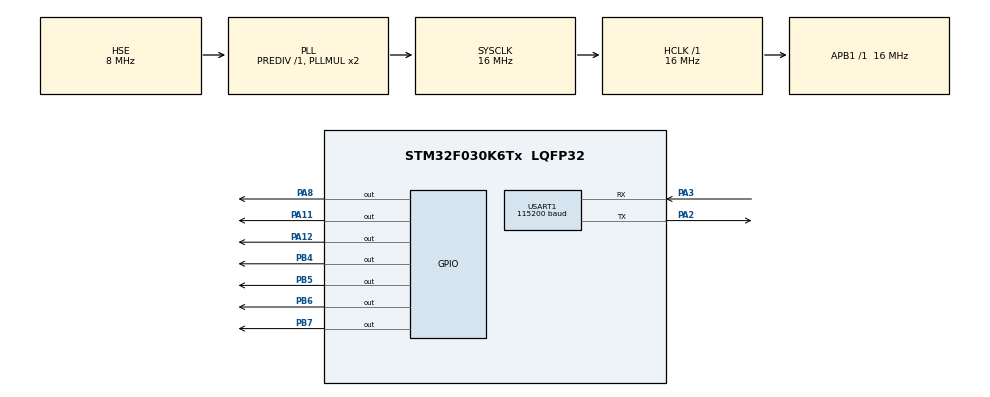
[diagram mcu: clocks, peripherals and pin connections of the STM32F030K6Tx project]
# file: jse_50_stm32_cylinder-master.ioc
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Mcu.Family=STM32F0
Mcu.Name=STM32F030K6Tx
Mcu.Package=LQFP32
NVIC.TIM3_IRQn=true\:2\:0\:true\:false\:true\:true\:true
NVIC.USART1_IRQn=true\:1\:0\:true\:false\:true\:true\:true
PA11.Signal=GPIO_Output
PA12.GPIO_ModeDefaultOutputPP=GPIO_MODE_OUTPUT_PP
PA12.GPIO_PuPd=GPIO_NOPULL
PA12.GPIO_Speed=GPIO_SPEED_FREQ_LOW
PA12.PinState=GPIO_PIN_RESET
PA12.Signal=GPIO_Output
PA2.Mode=Asynchronous
PA2.Signal=USART1_TX
PA3.Mode=Asynchronous
PA3.Signal=USART1_RX
PA8.GPIO_ModeDefaultOutputPP=GPIO_MODE_OUTPUT_PP
PA8.GPIO_PuPd=GPIO_NOPULL
PA8.GPIO_Speed=GPIO_SPEED_FREQ_LOW
PA8.PinState=GPIO_PIN_RESET
PA8.Signal=GPIO_Output
PB4.GPIO_ModeDefaultOutputPP=GPIO_MODE_OUTPUT_PP
PB4.GPIO_PuPd=GPIO_NOPULL
PB4.GPIO_Speed=GPIO_SPEED_FREQ_LOW
PB4.PinState=GPIO_PIN_RESET
PB4.Signal=GPIO_Output
PB5.GPIO_ModeDefaultOutputPP=GPIO_MODE_OUTPUT_PP
PB5.GPIO_PuPd=GPIO_NOPULL
PB5.GPIO_Speed=GPIO_SPEED_FREQ_LOW
PB5.PinState=GPIO_PIN_RESET
PB5.Signal=GPIO_Output
PB6.GPIO_FM6=__NULL
PB6.GPIO_ModeDefaultOutputPP=GPIO_MODE_OUTPUT_PP
PB6.GPIO_PuPd=GPIO_NOPULL
PB6.GPIO_Speed=GPIO_SPEED_FREQ_LOW
PB6.PinState=GPIO_PIN_RESET
PB6.Signal=GPIO_Output
PB7.GPIO_FM7=__NULL
PB7.GPIO_ModeDefaultOutputPP=GPIO_MODE_OUTPUT_PP
PB7.GPIO_PuPd=GPIO_NOPULL
PB7.GPIO_Speed=GPIO_SPEED_FREQ_LOW
PB7.PinState=GPIO_PIN_RESET
PB7.Signal=GPIO_Output
PF0-OSC_IN.Mode=HSE-External-Oscillator
PF0-OSC_IN.Signal=RCC_OSC_IN
PF1-OSC_OUT.Mode=HSE-External-Oscillator
PF1-OSC_OUT.Signal=RCC_OSC_OUT
ProjectManager.HeapSize=0x200
ProjectManager.StackSize=0x400
ProjectManager.TargetToolchain=STM32CubeIDE
RCC.AHBFreq_Value=16000000
RCC.APB1Freq_Value=16000000
RCC.APB1TimFreq_Value=16000000
RCC.HCLKFreq_Value=16000000
RCC.PLLSourceVirtual=RCC_PLLSOURCE_HSE
RCC.PWREXT_OverDrive=PWREXT_OverDrive_ACTIVATED
RCC.PWR_Regulator_Voltage_Scale=PWR_REGULATOR_VOLTAGE_SCALE1
RCC.RCC_TIM_PRescaler_Selection=RCC_TIMPRES_DESACTIVATED
RCC.SYSCLKFreq_VALUE=16000000
RCC.SYSCLKSource=RCC_SYSCLKSOURCE_PLLCLK
TIM3.Channel-Output\ Compare1\ No\ Output=TIM_CHANNEL_1
TIM3.Period=500
TIM3.Prescaler=15999
USART1.BaudRate=115200
USART1.VirtualMode-Asynchronous=VM_ASYNC
VP_TIM3_VS_ClockSourceINT.Mode=Internal
VP_TIM3_VS_no_output1.Mode=Output Compare1 No Output
board=custom

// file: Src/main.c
/* USER CODE BEGIN Header */
/**
 ******************************************************************************
 * @file           : main.c
 * @brief          : Main program body
 ******************************************************************************
 * @attention
 *
 * <h2><center>&copy; Copyright (c) 2019 STMicroelectronics.
 * All rights reserved.</center></h2>
 *
 * This software component is licensed by ST under BSD 3-Clause license,
 * the "License"; You may not use this file except in compliance with the
 * License. You may obtain a copy of the License at:
 *                        opensource.org/licenses/BSD-3-Clause
 *
 ******************************************************************************
 */
/* USER CODE END Header */

#include "main.h"
#include "tim.h"
#include "usart.h"
#include "gpio.h"

/* USER CODE BEGIN Includes */

#include "led.h"
#include "ctrl.h"
#include "address.h"

/* USER CODE END Includes */

void SystemClock_Config(void);

int main(void)
{

  /* MCU Configuration--------------------------------------------------------*/

  /* Reset of all peripherals, Initializes the Flash interface and the Systick. */
  HAL_Init();

  /* Configure the system clock */
  SystemClock_Config();

  /* Initialize all configured peripherals */
  MX_GPIO_Init();
  MX_TIM3_Init();
  MX_USART1_UART_Init();
  /* USER CODE BEGIN 2 */

	CTRL_Init();
//	HAL_TIM_Base_Start_IT(&htim3);
	HAL_TIM_OC_Start_IT(&htim3,TIM_CHANNEL_1);

  /* USER CODE END 2 */

  /* Infinite loop */
  /* USER CODE BEGIN WHILE */
//	while (ADDRESS_INDEX == 0xFF)
		;
//		htim3.Instance->CCR1 = 500;
	while (1) {
//		CTRL_Work();
		HAL_Delay(5000);
//		TIM1->CCR1=160;
	//	htim3.Instance->CCR1 = 500;
//		htim1.Init.Period = 80;
//		HAL_TIM_Base_DeInit(&htim1);
//		HAL_TIM_Base_Start_IT(&htim1);

//		htim1.Instance->CNT = 0;
//		HAL_TIM_Base_Stop_IT(&htim1);
//		HAL_TIM_Base_Start_IT(&htim1);

    /* USER CODE END WHILE */

	}
}

void SystemClock_Config(void)
{
  RCC_OscInitTypeDef RCC_OscInitStruct = {0};
  RCC_ClkInitTypeDef RCC_ClkInitStruct = {0};
  RCC_PeriphCLKInitTypeDef PeriphClkInit = {0};

  /** Initializes the CPU, AHB and APB busses clocks
  */
  RCC_OscInitStruct.OscillatorType = RCC_OSCILLATORTYPE_HSE;
  RCC_OscInitStruct.HSEState = RCC_HSE_ON;
  RCC_OscInitStruct.PLL.PLLState = RCC_PLL_ON;
  RCC_OscInitStruct.PLL.PLLSource = RCC_PLLSOURCE_HSE;
  RCC_OscInitStruct.PLL.PLLMUL = RCC_PLL_MUL2;
  RCC_OscInitStruct.PLL.PREDIV = RCC_PREDIV_DIV1;
  if (HAL_RCC_OscConfig(&RCC_OscInitStruct) != HAL_OK)
  {
    Error_Handler();
  }
  /** Initializes the CPU, AHB and APB busses clocks
  */
  RCC_ClkInitStruct.ClockType = RCC_CLOCKTYPE_HCLK|RCC_CLOCKTYPE_SYSCLK
                              |RCC_CLOCKTYPE_PCLK1;
  RCC_ClkInitStruct.SYSCLKSource = RCC_SYSCLKSOURCE_PLLCLK;
  RCC_ClkInitStruct.AHBCLKDivider = RCC_SYSCLK_DIV1;
  RCC_ClkInitStruct.APB1CLKDivider = RCC_HCLK_DIV1;

  if (HAL_RCC_ClockConfig(&RCC_ClkInitStruct, FLASH_LATENCY_0) != HAL_OK)
  {
    Error_Handler();
  }
  PeriphClkInit.PeriphClockSelection = RCC_PERIPHCLK_USART1;
  PeriphClkInit.Usart1ClockSelection = RCC_USART1CLKSOURCE_PCLK1;
  if (HAL_RCCEx_PeriphCLKConfig(&PeriphClkInit) != HAL_OK)
  {
    Error_Handler();
  }
}

void Error_Handler(void)
{
}

/************************ (C) COPYRIGHT STMicroelectronics *****END OF FILE****/
